# GD32A72_A74x register map
File version: 1.0
CPU: CM7 r2p1, little endian, MPU, FPU, DSP, 4 interrupt priority bits
Registers are 32-bit, read-write, reset 0x0 unless marked. A register's access mark holds for its fields unless they carry their own. Offsets are from the block's base; [hi:lo] are bit positions; {n}, {i} and the like mark numbered series; 'fields as' and 'values as' point back to an identical list.

## EXTMPU — Extended memory protection unit
Base 0x4900A000
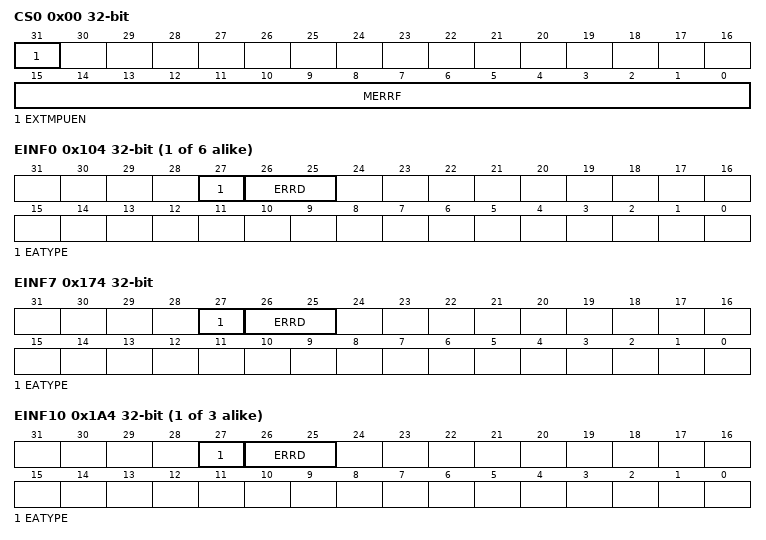
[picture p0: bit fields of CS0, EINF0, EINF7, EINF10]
0x00 CS0 — Control and status register 0
  [31] EXTMPUEN — Extended MPU enable
  [15:0] MERRF — Error flag of master x
0x04 CS1 ro — Control and status register 1
  [15:0] MOVF — Overrun flag of master x
{0x100+0x10*i} EADDR{i} ro (i=0..5) — Error address register {i}
  [31:0] ERRADDR — Error address bits
{0x104+0x10*i} EINF{i} ro (i=0..5) — Error information register {i}
  [27] EATYPE — Error access type
  [26:25] ERRD — Error detailed information
{0x108+0x10*i} EREG{i} (i=0..5) — Error region register {i}
  [31:0] EACINF — Error access control information bits
0x170 EADDR7 ro — Error address register 7
  [31:0] ERRADDR — Error address bits
0x174 EINF7 ro — Error information register 7
  fields as EINF0
0x178 EREG7 — Error region register 7
  [31:0] EACINF — Error access control information bits
{0x100+0x10*i} EADDR{i} ro (i=10..12) — Error address register {i}
  [31:0] ERRADDR — Error address bits
{0x104+0x10*i} EINF{i} ro (i=10..12) — Error information register {i}
  fields as EINF0
{0x108+0x10*i} EREG{i} (i=10..12) — Error region register {i}
  [31:0] EACINF — Error access control information bits
0x1E0 EADDR14 ro — Error address register 14
  [31:0] ERRADDR — Error address bits
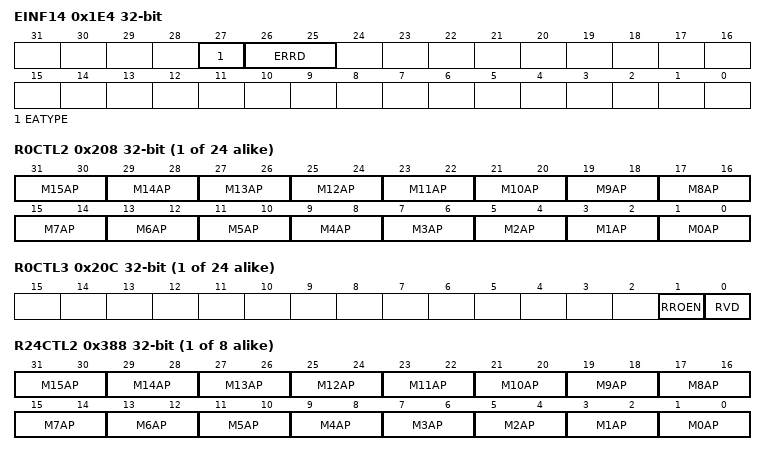
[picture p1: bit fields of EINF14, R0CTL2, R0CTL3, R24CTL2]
0x1E4 EINF14 ro — Error information register 14
  fields as EINF0
0x1E8 EREG14 — Error region register 14
  [31:0] EACINF — Error access control information bits
{0x200+0x10*i} R{i}CTL0 (i=0..23) — Region {i} control register 0
  [31:0] SADDR — Start address of region
{0x204+0x10*i} R{i}CTL1 (i=0..23) — Region {i} control register 1
  [31:0] EADDR — End address of region
{0x208+0x10*i} R{i}CTL2 (i=0..23) — Region {i} control register 2
  [2n+1:2n] M{n}AP (n=0..15) — Master {n} access permission
{0x20C+0x10*i} R{i}CTL3 (i=0..23) — Region {i} control register 3
  [1] RROEN — Region read only control bit
  [0] RVD — Region valid bit
{0x200+0x10*i} R{i}CTL0 (i=24..31) — Region 23 control register 0
  [31:0] SADDR — Start address of region
{0x204+0x10*i} R{i}CTL1 (i=24..31) — Region 23 control register 1
  [31:0] EADDR — End address of region
{0x208+0x10*i} R{i}CTL2 (i=24..31) — Region 23 control register 2
  [2n+1:2n] M{n}AP (n=0..15) — Master {n} access permission
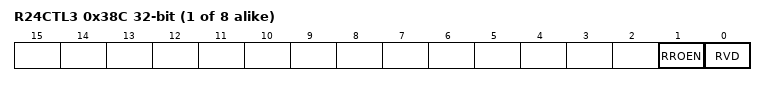
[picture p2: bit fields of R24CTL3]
{0x20C+0x10*i} R{i}CTL3 (i=24..31) — Region 23 control register 3
  fields as R0CTL3

## FWDGT0 — Free watchdog timer
Base 0x40003000
Same registers: FWDGT1 0x4000E000
0x00 CTL wo — Control register
  [15:0] CMD — FWDGT command
0x04 PSC — Prescaler register
  [2:0] PSC — Free watchdog timer prescaler selection
0x08 RLD reset 0xFFFFF — Reload register
  [19:0] RLD — Free watchdog timer counter reload value
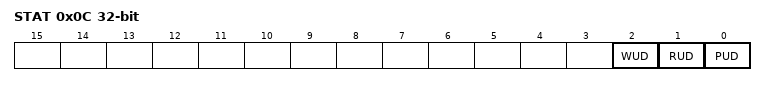
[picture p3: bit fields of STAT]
0x0C STAT ro — Status register
  [2] WUD — Watchdog counter window value update
  [1] RUD — Free watchdog timer counter reload value update
  [0] PUD — Free watchdog timer prescaler value update
0x10 WND reset 0xFFFFF — Window register
  [19:0] WND — Watchdog counter window value

## GD_AP — Debug system GD_AP
Base 0x40250400
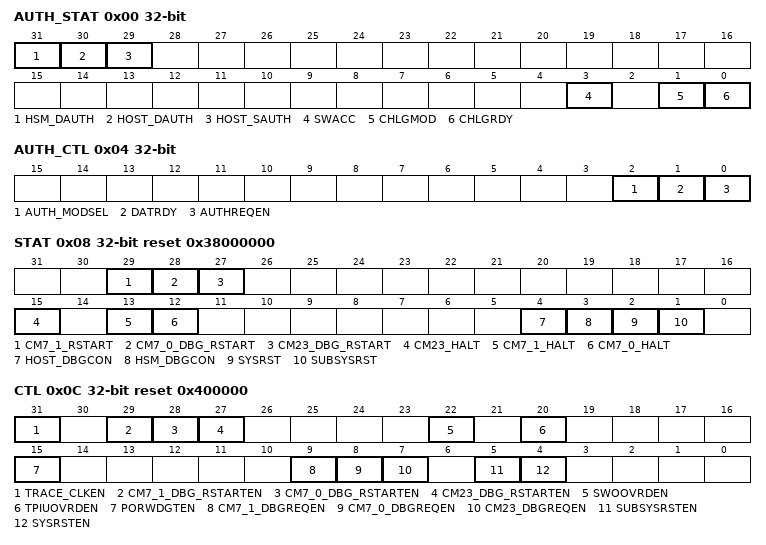
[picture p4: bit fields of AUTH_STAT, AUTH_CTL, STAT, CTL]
0x00 AUTH_STAT ro — Authentication status register
  [31] HSM_DAUTH — HSM dynamic authentication status
  [30] HOST_DAUTH — Host dynamic authentication success, CR is statisfied and allows access to other APs
  [29] HOST_SAUTH — Host static authentication success
  [3] SWACC — Debug software access enable
  [1] CHLGMOD — Challenge mode status
  [0] CHLGRDY — Challenge ready
0x04 AUTH_CTL — Authentication control register
  [2] AUTH_MODSEL — Authentication mode selection
  [1] DATRDY — Indicates the data is ready for static authentication
  [0] AUTHREQEN — Debug authentication request enable
0x08 STAT ro reset 0x38000000 — Status register
  [29] CM7_1_RSTART — Core CM7_1 debug restarted
  [28] CM7_0_DBG_RSTART — Core CM7_0 debug restarted
  [27] CM23_DBG_RSTART — Core CM23 debug restarted
  [15] CM23_HALT — MCU entry debug mode, core CM23 is halted
  [13] CM7_1_HALT — MCU entry debug mode, core CM7_1 is halted
  [12] CM7_0_HALT — MCU entry debug mode, core CM7_0 is halted
  [4] HOST_DBGCON — HOST debug connect status
  [3] HSM_DBGCON — HSM debug connect status
  [2] SYSRST — Subsystem reset state
  [1] SUBSYSRST — System reset state
0x0C CTL reset 0x400000 — Control register
  [31] TRACE_CLKEN — Trace clock enable
  [29] CM7_1_DBG_RSTARTEN — Core CM7_1 debug restarted enable
  [28] CM7_0_DBG_RSTARTEN — Core CM7_0 debug restarted enable
  [27] CM23_DBG_RSTARTEN — Core CM23 debug restarted enable
  [22] SWOOVRDEN — SWO override enable
  [20] TPIUOVRDEN — TPIU override enable
  [15] PORWDGTEN — Power watchdog
  [9] CM7_1_DBGREQEN — Core CM7_1 debug request enable
  [8] CM7_0_DBGREQEN — Core CM7_0 debug request enable
  [7] CM23_DBGREQEN — Core CM23 debug request enable
  [5] SUBSYSRSTEN — Subsystem reset enable
  [4] SYSRSTEN — System reset enable
{0x10+4i} KEYCHLG{i} ro (i=0..3) — Key challenge register {i}
  [31:0] KEYCHLG — Debug enablement key challenge
0x30 LPCTL0 — Low power control register 0
  [0] LPDBGEN — Low power debug mode enable
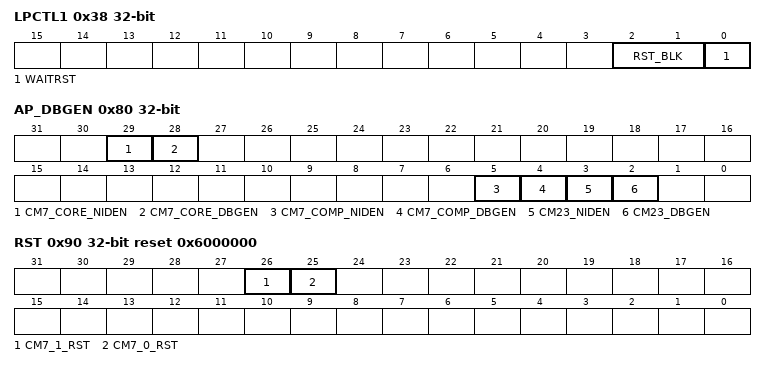
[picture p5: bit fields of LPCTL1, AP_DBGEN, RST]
0x38 LPCTL1 — Low power control register 1
  [2:1] RST_BLK — Reset block
  [0] WAITRST — Support for wait NRST pin
{0x40+4i} KEYRESP{i} (i=0..3) — Key response register {i}
  [31:0] KEYRESP — Debug enablement key response
0x80 AP_DBGEN — Debug enable register
  [29] CM7_CORE_NIDEN — Core CM7 non-invasive debug enable
  [28] CM7_CORE_DBGEN — Core CM7 debug enable
  [5] CM7_COMP_NIDEN — CM7 subsysterm, ITM, ETM and CTI compoment non-invasive debug enable
  [4] CM7_COMP_DBGEN — CM7 subsysterm, ITM, ETM and CTI compoment debug enable
  [3] CM23_NIDEN — Core CM23 non-invasive debug enable
  [2] CM23_DBGEN — Core CM23 debug enable
0x90 RST reset 0x6000000 — Reset register
  [26] CM7_1_RST — Core CM7_1 reset release
  [25] CM7_0_RST — Core CM7_0 reset release
0xFC ID ro — ID code register
  [31:0] ID_CODE — JTAG ID code
